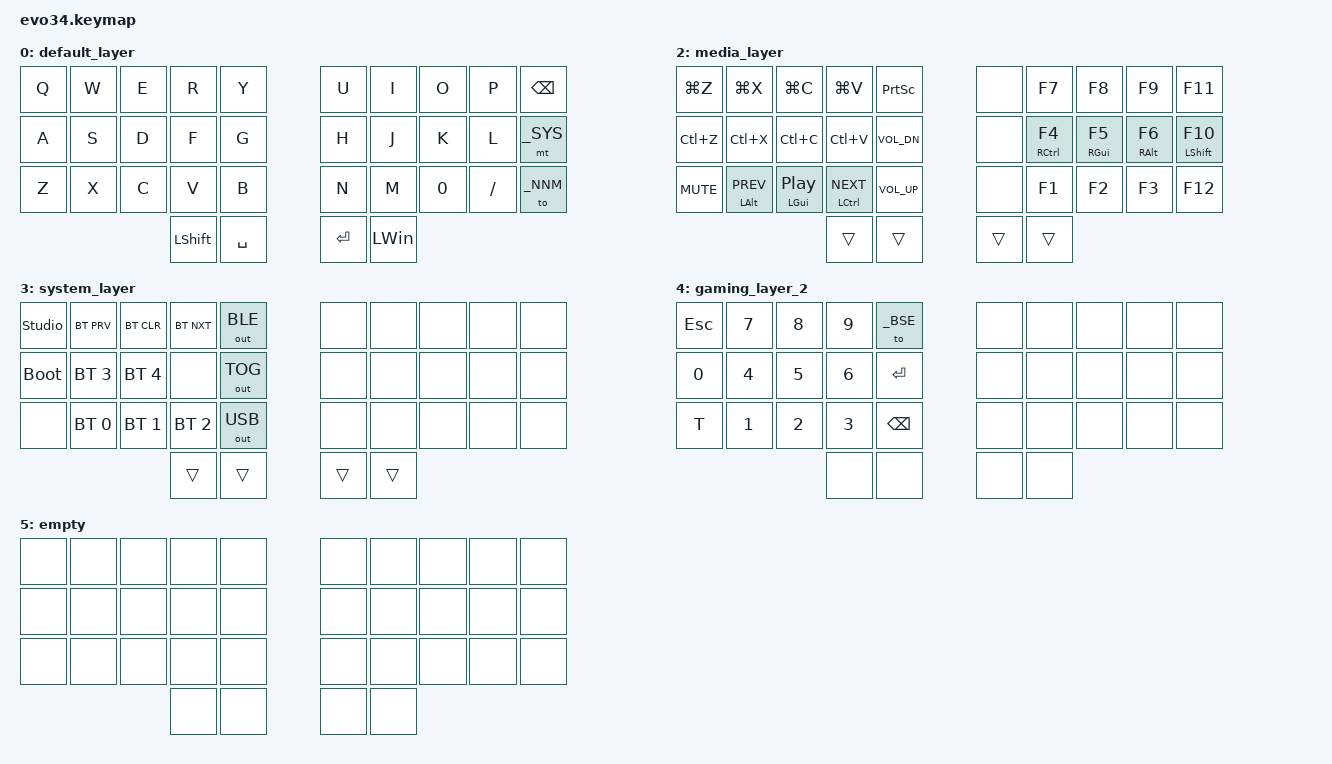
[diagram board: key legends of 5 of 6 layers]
/*
 * Copyright (c) 2020 The ZMK Contributors
 *
 * SPDX-License-Identifier: MIT
 */

#include <behaviors.dtsi>
#include <dt-bindings/zmk/bt.h>
#include <dt-bindings/zmk/keys.h>
#include <dt-bindings/zmk/outputs.h>

// LAYERS
#define _BSE 0
#define _NNM 1
#define _MED 2
#define _SYS 3
#define _GM2 5

&mt {
  flavor = "tap-preferred";
  tapping-term-ms = <200>;
  quick-tap-ms = <200>;
};

&lt {
  flavor = "tap-preferred";
  tapping-term-ms = <200>;
  quick-tap-ms = <200>;
};

&sl {
    release-after-ms = <1000>;
};

&sk {
    release-after-ms = <500>;
    quick-release;
};

/ {
  behaviors {
    hmt: hold_preferred_mod_tap {
      compatible = "zmk,behavior-hold-tap";
      #binding-cells = <2>;
      tapping-term-ms = <200>;
      quick-tap-ms = <0>;
      flavor = "hold-preferred";
      bindings = <&kp>, <&kp>;
    };
    hlt: hold_preferred_layer_tap {
      compatible = "zmk,behavior-hold-tap";
      #binding-cells = <2>;
      tapping-term-ms = <200>;
      quick-tap-ms = <0>;
      flavor = "hold-preferred";
      bindings = <&mo>, <&kp>;
    };
  };

 keymap {
    compatible = "zmk,keymap";

    default_layer {
      bindings = <
        &kp Q            &kp W            &kp E            &kp R           &kp Y                 &kp U             &kp I           &kp O            &kp P            &kp BSPC
        &kp A            &kp S            &kp D            &kp F           &kp G                 &kp H             &kp J           &kp K            &kp L            &mt _SYS
        &kp Z            &kp X            &kp C            &kp V           &kp B                 &kp N             &kp M           &kp N0           &kp FSLH         &to _NNM
                                                           &kp LSHIFT      &kp SPC               &kp ENTER         &kp LEFT_WIN
      >;
    };

    nnm_layer {
      bindings = <
        &kp ESC          &kp N1           &kp N2           &kp N3           &kp N4                &kp N5           &kp N6           &kp N7           &kp N8           &kp N9
        &mt LSHIFT BSPC  &kp LALT LEFT    &kp LGUI DOWN    &kp LCTRL RIGHT  &kp LBKT              &kp EQUAL        &kp RCTRL N4     &kp RGUI N5      &kp RALT N6      &kp RSHIFT N0
        &kp HOME         &kp PG_UP        &kp PG_DN        &mt LSHIFT END   &kp RBKT              &kp MINUS        &kp N1           &kp N2           &kp N3           &kp DOT 
                                                           &trans           &trans                &trans           &trans
      >;
    };

    media_layer {
      bindings = <
        &kp LG(Z)        &kp LG(X)        &kp LG(C)        &kp LG(V)        &kp PSCRN            &none            &kp F7           &kp F8           &kp F9           &kp F11
        &kp LC(Z)        &kp LC(X)        &kp LC(C)        &kp LC(V)        &kp C_VOL_DN         &none            &mt RCTRL F4     &mt RGUI F5      &mt RALT F6      &mt LSHIFT F10
        &kp C_MUTE       &mt LALT C_PREV  &mt LGUI C_PP    &mt LCTRL C_NEXT &kp C_VOL_UP         &none            &kp F1           &kp F2           &kp F3           &kp F12
                                                           &trans           &trans               &trans           &trans
      >;
    };

    system_layer {
      bindings = <
        &studio_unlock   &bt BT_PRV       &bt BT_CLR       &bt BT_NXT       &out OUT_BLE          &none            &none            &none            &none            &none
        &bootloader      &bt BT_SEL 3     &bt BT_SEL 4     &none            &out OUT_TOG          &none            &none            &none            &none            &none
        &none            &bt BT_SEL 0     &bt BT_SEL 1     &bt BT_SEL 2     &out OUT_USB          &none            &none            &none            &none            &none
                                                           &trans           &trans                &trans           &trans
      >;
    };

    
    gaming_layer_2 {
      bindings = <
        &kp ESC         &kp N7           &kp N8            &kp N9           &to _BSE              &none            &none            &none            &none            &none
        &kp N0          &kp N4           &kp N5            &kp N6           &kp RET               &none            &none            &none            &none            &none
        &kp T           &kp N1           &kp N2            &kp N3           &kp BSPC              &none            &none            &none            &none            &none
                                                           &none            &none                 &none            &none
      >;
    };

    empty {
      bindings = <
        &none           &none            &none             &none            &none                 &none            &none            &none            &none            &none
        &none           &none            &none             &none            &none                 &none            &none            &none            &none            &none
        &none           &none            &none             &none            &none                 &none            &none            &none            &none            &none
                                                           &none            &none                 &none            &none
      >;
    };
  };
};
